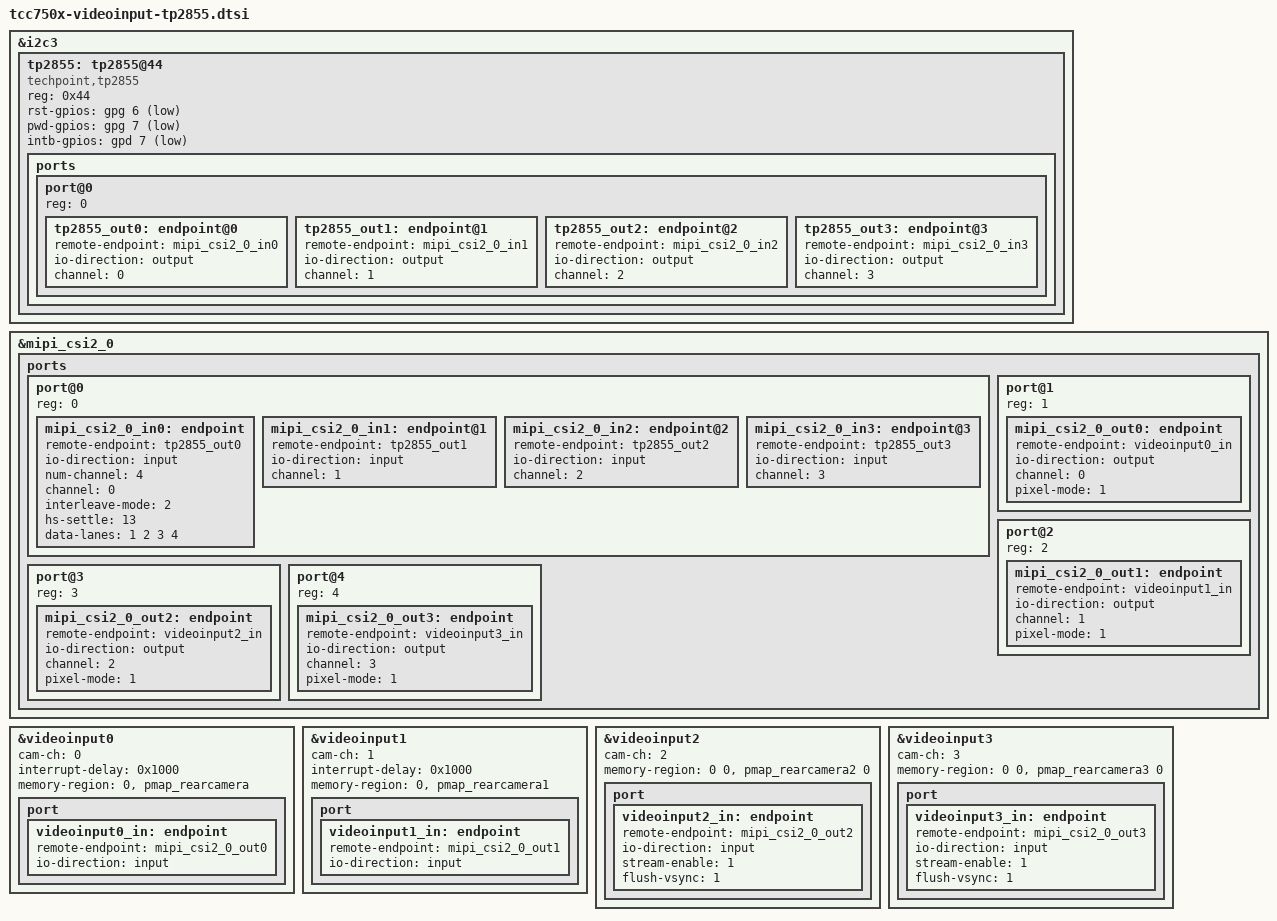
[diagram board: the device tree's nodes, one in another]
// SPDX-License-Identifier: (GPL-2.0-or-later OR MIT)
/*
 * Copyright (C) Telechips Inc.
 */

&i2c3 {
    tp2855: tp2855@44 {
        compatible = "techpoint,tp2855";
        status = "okay";
        reg = <0x44>;

        rst-gpios = <&gpg 6 1>;
        pwd-gpios = <&gpg 7 1>;
        intb-gpios = <&gpd 7 1>;
        ports {
            #address-cells = <1>;
            #size-cells = <0>;
            port@0 {
                reg = <0>;
                tp2855_out0: endpoint@0 {
                    remote-endpoint = <&mipi_csi2_0_in0>;
                    io-direction = "output";
                    channel = <0>;
                };

                tp2855_out1: endpoint@1 {
                    remote-endpoint = <&mipi_csi2_0_in1>;
                    io-direction = "output";
                    channel = <1>;
                };
                tp2855_out2: endpoint@2 {
                    remote-endpoint = <&mipi_csi2_0_in2>;
                    io-direction = "output";
                    channel = <2>;
                };
                tp2855_out3: endpoint@3 {
                    remote-endpoint = <&mipi_csi2_0_in3>;
                    io-direction = "output";
                    channel = <3>;
                };

            };
        };
    };
};

/*&max9286 {
    status          = "disabled";
    ports {
        port@4 {
            reg = <4>;
            max9286_out: endpoint {
                remote-endpoint = <&mipi_csi2_0_in0>;
                io-direction    = "output";
            };
        };
    };
};*/

&mipi_csi2_0 {
	status = "okay";
	ports {
		port@0 {
			reg = <0>;
			mipi_csi2_0_in0: endpoint {
				remote-endpoint = <&tp2855_out0>;
				io-direction    = "input";
				num-channel     = <4>;
				channel = <0>;
				/*
				* 0: CH0 only, no data interleave
				* 1: DT only
				* 2: VC only
				* 3: VC and DT
				*/
				interleave-mode = <2>;
				hs-settle = <13>;
				data-lanes = <1 2 3 4>;
				};
			mipi_csi2_0_in1: endpoint@1 {
				remote-endpoint = <&tp2855_out1>;
				io-direction = "input";
				channel = <1>;
			};
			mipi_csi2_0_in2: endpoint@2 {
				remote-endpoint = <&tp2855_out2>;
				io-direction = "input";
				channel = <2>;
			};
			mipi_csi2_0_in3: endpoint@3 {
				remote-endpoint = <&tp2855_out3>;
				io-direction = "input";
				channel = <3>;
			};
		};
		port@1 {
			reg = <1>;
			mipi_csi2_0_out0: endpoint {
				remote-endpoint = <&videoinput0_in>;
				io-direction = "output";
				channel = <0>;
				pixel-mode = <1>;
			};
		};
		port@2 {
			reg = <2>;
			mipi_csi2_0_out1: endpoint {
				remote-endpoint = <&videoinput1_in>;
				io-direction = "output";
				channel = <1>;
				pixel-mode = <1>;
			};
		};
		port@3 {
			reg = <3>;
			mipi_csi2_0_out2: endpoint {
				remote-endpoint = <&videoinput2_in>;
				io-direction = "output";
				channel = <2>;
				pixel-mode = <1>;
			};
		};
		port@4 {
			reg = <4>;
			mipi_csi2_0_out3: endpoint {
				remote-endpoint = <&videoinput3_in>;
				io-direction = "output";
				channel = <3>;
				pixel-mode = <1>;
			};
		};
    	};
};

&videoinput0 {
	status = "okay";
	cam-ch = <0>;
	interrupt-delay = <0x1000>;
	memory-region = <0 &pmap_rearcamera>;
	port {
		videoinput0_in: endpoint {
			remote-endpoint = <&mipi_csi2_0_out0>;
			io-direction = "input";
		};
	};
};

&videoinput1 {
	status = "okay";
	cam-ch = <1>;
	interrupt-delay = <0x1000>;
	memory-region = <0 &pmap_rearcamera1>;
	port {
		videoinput1_in: endpoint {
			remote-endpoint = <&mipi_csi2_0_out1>;
			io-direction = "input";
		};
	};
};

&videoinput2 {
	status = "okay";
	cam-ch = <2>;
	memory-region = <0 0 &pmap_rearcamera2 0>;
	port {
		videoinput2_in: endpoint {
			remote-endpoint = <&mipi_csi2_0_out2>;
			io-direction = "input";
			stream-enable = <1>;
			flush-vsync = <1>;
		};
	};
};

&videoinput3 {
	status = "okay";
	cam-ch = <3>;
	memory-region = <0 0 &pmap_rearcamera3 0>;
	port {
		videoinput3_in: endpoint {
			remote-endpoint = <&mipi_csi2_0_out3>;
			io-direction = "input";
			stream-enable = <1>;
			flush-vsync = <1>;
		};
	};
};
